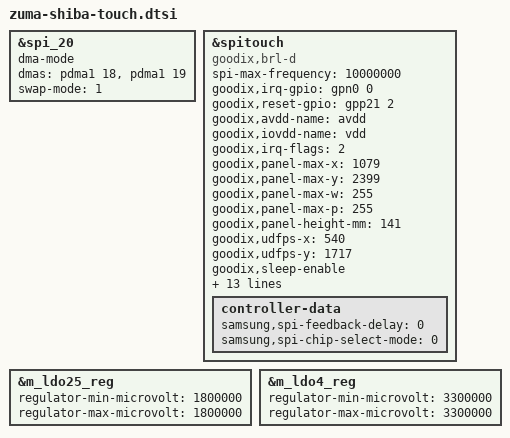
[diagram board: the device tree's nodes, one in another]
// SPDX-License-Identifier: GPL-2.0-only
/*
 * Google Shiba touch device tree source
 *
 * Copyright 2022 Google LLC.
 *
 */

#include "../google-dts-base/zuma-common-touch.dtsi"

&spi_20 {
	status = "okay";
	dma-mode;
	dmas = <&pdma1 18 &pdma1 19>;
	swap-mode = <1>;
};

&spitouch {
	status = "ok";
	compatible = "goodix,brl-d";

	spi-max-frequency = <10000000>;

	goodix,irq-gpio = <&gpn0 0 0>;
	goodix,reset-gpio = <&gpp21 2 0>;
	goodix,avdd-name = "avdd";
	goodix,iovdd-name = "vdd";
	goodix,irq-flags = <2>; /* 1:trigger rising, 2:trigger falling;*/
	goodix,panel-max-x = <1079>;
	goodix,panel-max-y = <2399>;
	goodix,panel-max-w = <255>;
	goodix,panel-max-p = <255>;
	goodix,panel-height-mm = <141>;
	goodix,udfps-x = <540>;
	goodix,udfps-y = <1717>;
	goodix,sleep-enable;

	goodix,panel_map = <&google_bigsurf 0>,
			<&google_shoreline 1>;

	goodix,firmware_names = "goodix_firmware.bin",
			"goodix_firmware.bin";

	goodix,config_names = "goodix_cfg_group_bigsurf.bin",
			"goodix_cfg_group_shoreline.bin";

	goodix,test_limits_names = "goodix_test_limits_bigsurf.csv",
			"goodix_test_limits_shoreline.csv";

	goog,touch_offload_id = /bits/ 8 <'s' 'b' '3' '0'>;
	goog,display-resolution = /bits/ 16 <1080 2400>;
	goog,channel-num = /bits/ 16 <16 36>;

	controller-data {
		samsung,spi-feedback-delay = <0>;
		samsung,spi-chip-select-mode = <0>;
	};
};

&m_ldo25_reg {
	regulator-min-microvolt = <1800000>;
	regulator-max-microvolt = <1800000>;
	/delete-property/ regulator-always-on;
};

&m_ldo4_reg {
	regulator-min-microvolt = <3300000>;
	regulator-max-microvolt = <3300000>;
	/delete-property/ regulator-always-on;
};
